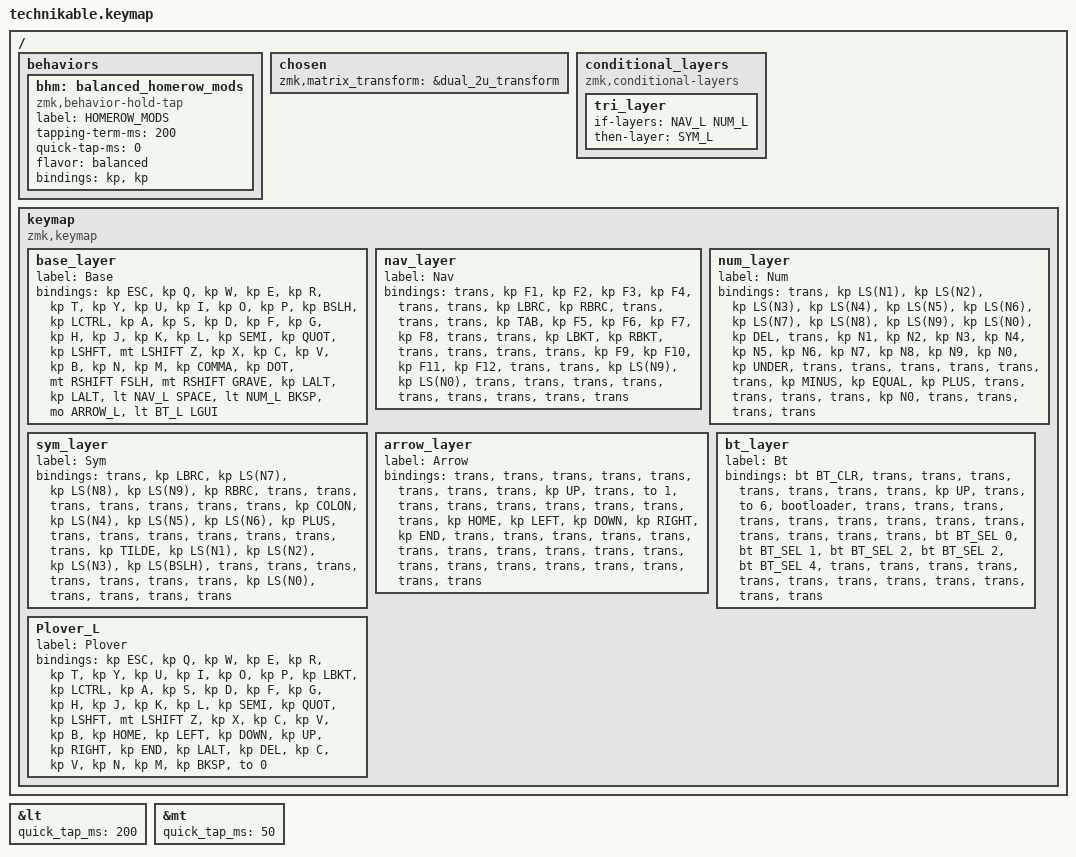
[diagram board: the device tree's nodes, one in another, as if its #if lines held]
/*
 * Copyright (c) 2022 Pete Johanson
 *
 * SPDX-License-Identifier: MIT
 */

#include <behaviors.dtsi>
#include <dt-bindings/zmk/keys.h>
#include <dt-bindings/zmk/bt.h>
#include <dt-bindings/zmk/outputs.h>

#define QWERTY_BASE 1

 #define TBLE_ORTHO   true
// #define TBLE_MIT     true
// #define TBLE_DUAL_2U true

#define BAS_L 0
#define NAV_L 1
#define NUM_L 2
#define SYM_L 3
#define ARROW_L 4
#define BT_L 5
#define Plover_L 6

// Using layer taps on thumbs, having quick tap as well helps w/ repeating space/backspace
&lt { quick_tap_ms = <200>; };
&mt { quick_tap_ms = <50>; };

#define BT(n) BT_SEL n

/ {
   behaviors {
        bhm: balanced_homerow_mods {
            compatible = "zmk,behavior-hold-tap";
            label = "HOMEROW_MODS";
            #binding-cells = <2>;
            tapping-term-ms = <200>;    // <---[[moderate duration]]
            quick-tap-ms = <0>;
            flavor = "balanced";
            bindings = <&kp>, <&kp>;
        };
    };


    chosen {
       zmk,matrix_transform =
#ifdef TBLE_DUAL_2U
                       &dual_2u_transform;
#elif defined(TBLE_MIT)
                       &mit_transform;
#else
                       &ortho_transform;
#endif
    };
    

    conditional_layers {
        compatible = "zmk,conditional-layers";
	    tri_layer {
	      if-layers = <NAV_L NUM_L>;
	      then-layer = <SYM_L>;
	    };
    };

    keymap {
        compatible = "zmk,keymap";

        base_layer {
            label = "Base";
            bindings = <
// &kp LCTRL &bhm LCTRL  A
// --------------------------------------------------------------------------------------
//   | ESC  |  Q  |  W  |  E  |  R  |  T  |    |  Y  |  U   |  I  |  O  |  P  |  \   | 
//   | CTRL |  A  |  S  |  D  |  F  |  G  |    |  H  |  J   |  K  |  L  |  ;  |  '   |
//   |LSHFT |  Z  |  X  |  C  |  V  |  B  |    |  N  |  M   |  ,  |  .  |  /  |  `   |
//                | ALT | SPC | LWR | SPC |    | LWR | BKSP | RSE | GUI |
// --------------------------------------------------------------------------------------
 &kp ESC   &kp Q   &kp W   &kp E   &kp R    &kp T    &kp Y   &kp U    &kp I       &kp O     &kp P      &kp BSLH
 &kp LCTRL &kp A   &kp S   &kp D   &kp F    &kp G    &kp H   &kp J    &kp K       &kp L     &kp SEMI   &kp QUOT
 &kp LSHFT &mt LSHIFT Z   &kp X   &kp C   &kp V    &kp B    &kp N   &kp M    &kp COMMA   &kp DOT   &mt RSHIFT FSLH   &mt RSHIFT GRAVE
 
#ifdef TBLE_DUAL_2U
    &kp LALT  &kp LALT      &lt NAV_L SPACE                &lt NUM_L BKSP              &mo ARROW_L    &lt BT_L LGUI
#elif defined(TBLE_MIT)
    &kp LALT  &kp LALT    &mo NAV_L          &kp SPACE                   &mo NUM_L      &kp RALT    &kp RCTRL
#else
    &kp LALT  &kp LALT    &lt NAV_L SPACE    &kp SPACE     &lt NUM_L BKSP  &lt ARROW_L RET    &mo ARROW_L    &lt BT_L LGUI
#endif
            >;
        };

        nav_layer {
            label = "Nav";
            bindings = <
// --------------------------------------------------------------------------------------
//   | ESC  |  F1 |  F2 |  F3 |  F4 |   |    |  { |  }   |     |     |     |      | 
//   | CTRL |  F5 |  F6 |  F7 |  F8 |   |    |  [ |  ]   |     |     |     |      |
//   |LSHFT |  F9 | F10 | F11 | F12 |   |    |  ( |  )   |     |     |     |      |
//                |     |     |     |   |    |    |      |     |     |
// --------------------------------------------------------------------------------------
&trans   &kp F1 &kp F2  &kp F3  &kp F4  &trans &trans  &kp LBRC    &kp RBRC  &trans &trans &trans 
&kp TAB  &kp F5 &kp F6  &kp F7  &kp F8  &trans &trans  &kp LBKT    &kp RBKT  &trans &trans &trans 
&trans   &kp F9 &kp F10 &kp F11 &kp F12 &trans &trans  &kp LS(N9)  &kp LS(N0)    &trans &trans &trans 
#ifdef TBLE_DUAL_2U
                      &trans     &trans              &trans                    &trans       &trans         &trans
#elif defined(TBLE_MIT)
                      &trans     &trans      &trans                &trans             &trans      &trans   &trans
#else
                      &trans     &trans      &trans          &trans       &trans    &trans  &trans         &trans
#endif
            >;
        };


        num_layer {
            label = "Num";
            bindings = <
// --------------------------------------------------------------------------------------
//   |    |  !  |  @  |  #  |  $  |  %  |    | ^  |  &   |  *  |  (  |  )  |  DEL | 
//   |    |  1  |  2  |  3  |  4  |  5  |    | 6  |  7   |  8  |  9  |  0  |  _   |
//   |    |     |     |     |     |     |    | -  |  =   |  +  |      |    |      |
// --------------------------------------------------------------------------------------
&trans   &kp LS(N1)   &kp LS(N2) &kp LS(N3) &kp LS(N4)  &kp LS(N5) &kp LS(N6) &kp LS(N7)  &kp LS(N8)  &kp LS(N9)  &kp LS(N0) &kp DEL        
&trans   &kp N1       &kp N2     &kp N3     &kp N4      &kp N5     &kp N6     &kp N7      &kp N8      &kp N9      &kp N0     &kp UNDER
&trans   &trans       &trans     &trans     &trans      &trans     &kp MINUS  &kp EQUAL   &kp PLUS    &trans     &trans      &trans 
#ifdef TBLE_DUAL_2U
                     &trans     &kp N0              &trans                 &trans            &trans         &trans
#elif defined(TBLE_MIT)
                     &trans     &kp N0      &trans           &none            &kp ESC        &kp DEL      &trans
#else
                     &trans     &kp N0      &trans    &none         &none     &kp ESC        &kp DEL      &trans
#endif
            >;
        };

        sym_layer {
            label = "Sym";
            bindings = <
&trans     &kp LBRC   &kp LS(N7) &kp LS(N8)  &kp LS(N9)   &kp RBRC     &trans     &trans    &trans       &trans       &trans     &trans
&trans     &kp COLON  &kp LS(N4) &kp LS(N5)  &kp LS(N6)   &kp PLUS     &trans     &trans    &trans       &trans       &trans     &trans
&trans     &kp TILDE  &kp LS(N1) &kp LS(N2)  &kp LS(N3)   &kp LS(BSLH) &trans     &trans    &trans       &trans       &trans     &trans
#ifdef TBLE_DUAL_2U
                      &trans     &kp LS(N0)              &trans                    &trans       &trans         &trans
#elif defined(TBLE_MIT)
                      &trans     &kp LS(N0)      &trans                &trans             &trans      &trans   &trans
#else
                      &trans     &kp LS(N0)      &trans          &trans       &trans    &trans  &trans         &trans
#endif
            >;
        };

        arrow_layer {
            label = "Arrow";
            bindings = <
&trans  &trans  &trans  &trans  &trans  &trans  &trans  &trans  &kp UP  &trans  &to 1  &trans  
&trans  &trans  &trans  &trans  &trans  &trans  &kp HOME  &kp LEFT  &kp DOWN  &kp RIGHT  &kp END  &trans  
&trans  &trans  &trans  &trans  &trans  &trans  &trans  &trans  &trans  &trans  &trans  &trans  
#ifdef TBLE_DUAL_2U
                      &trans     &trans              &trans                    &trans       &trans         &trans
#elif defined(TBLE_MIT)
                      &trans     &trans      &trans                &trans             &trans      &trans   &trans
#else
                      &trans     &trans      &trans          &trans       &trans    &trans  &trans         &trans
#endif
            >;
        };


bt_layer {
            label = "Bt";
            bindings = <
&bt BT_CLR  &trans  &trans  &trans  &trans  &trans  &trans  &trans  &kp UP  &trans  &to 6 &bootloader  
&trans  &trans  &trans  &trans  &trans  &trans   &trans  &trans &trans &trans &trans &trans
&trans  &bt BT_SEL 0 &bt BT_SEL 1  &bt BT_SEL 2   &bt BT_SEL 2   &bt BT_SEL 4   &trans  &trans  &trans  &trans  &trans  &trans  
#ifdef TBLE_DUAL_2U
                      &trans     &trans              &trans                    &trans       &trans         &trans
#elif defined(TBLE_MIT)
                      &trans     &trans      &trans                &trans             &trans      &trans   &trans
#else
                      &trans     &trans      &trans          &trans       &trans    &trans  &trans         &trans
#endif
            >;
        };


Plover_L {
            label = "Plover";
            bindings = <
// &kp LCTRL &bhm LCTRL  A
// --------------------------------------------------------------------------------------
//   | ESC  |  Q  |  W  |  E  |  R  |  T  |    |  Y  |  U   |  I  |  O  |  P  |   [  | 
//   | CTRL |  A  |  S  |  D  |  F  |  G  |    |  H  |  J   |  K  |  L  |  ;  |  '   |
//   |LSHFT |  Z  |  X  |  C  |  V  |  B  |    | home| left | up  | down|right| end  |
//                | ALT | DEL |  C  |  V  |    |  N  |  M   | BKSP | TO(0) |
// --------------------------------------------------------------------------------------
 &kp ESC   &kp Q   &kp W   &kp E   &kp R    &kp T    &kp Y   &kp U    &kp I       &kp O     &kp P      &kp LBKT
 &kp LCTRL &kp A   &kp S   &kp D   &kp F    &kp G    &kp H   &kp J    &kp K       &kp L     &kp SEMI   &kp QUOT
 &kp LSHFT &mt LSHIFT Z   &kp X   &kp C   &kp V    &kp B    &kp HOME   &kp LEFT   &kp DOWN   &kp UP   &kp RIGHT   &kp END
 

 &kp LALT  &kp DEL    &kp C    &kp V    &kp N  &kp M     &kp BKSP      &to  0  

            >;
        };


    };
};

